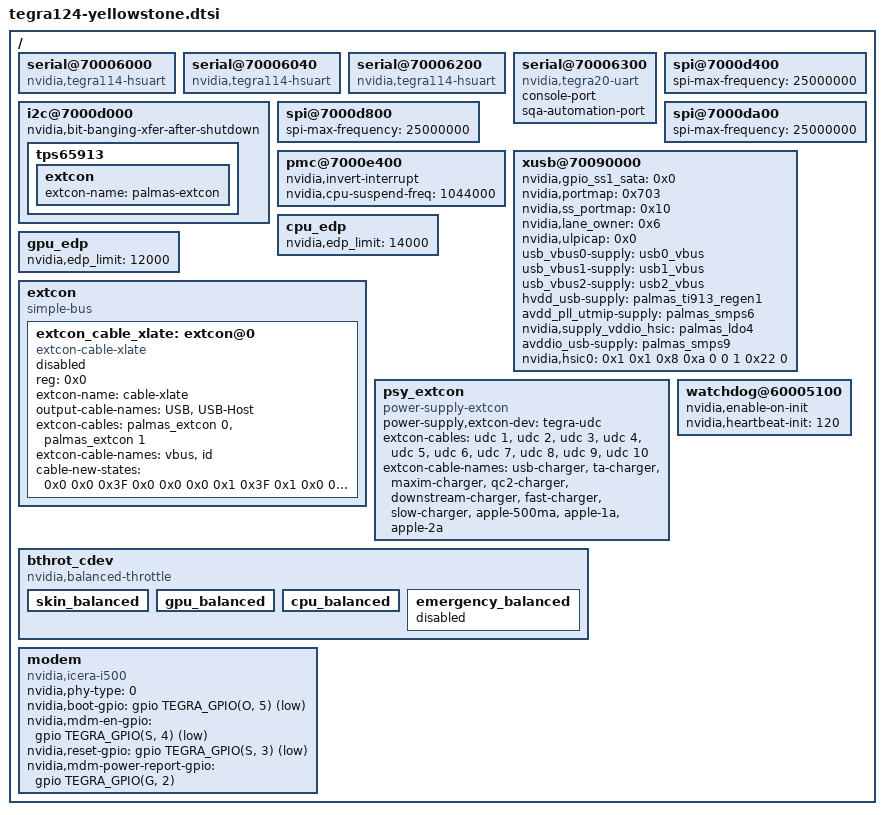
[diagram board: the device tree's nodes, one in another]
/*
 * tegra124-soc-shiled.dtsi: Shiled family SoC specific DTSI file with required node enabled.
 *
 * Copyright (c) 2013-2014, NVIDIA CORPORATION. All rights reserved.
 *
 * This program is free software; you can redistribute it and/or modify it
 * under the terms and conditions of the GNU General Public License,
 * version 2, as published by the Free Software Foundation.
 *
 * This program is distributed in the hope it will be useful, but WITHOUT
 * ANY WARRANTY; without even the implied warranty of MERCHANTABILITY or
 * FITNESS FOR A PARTICULAR PURPOSE.  See the GNU General Public License for
 * more details.
 */

#include "tegra124-soc-yellowstone.dtsi"
#include "tegra124-platforms/tegra124-yellowstone-cpufreq.dtsi"

/ {
	serial@70006000 {
		compatible = "nvidia,tegra114-hsuart";
		status = "okay";
	};

	serial@70006040 {
		compatible = "nvidia,tegra114-hsuart";
		status = "okay";
	};

	serial@70006200 {
		compatible = "nvidia,tegra114-hsuart";
		status = "okay";
	};

	serial@70006300 {
		compatible = "nvidia,tegra20-uart", "nvidia,tegra114-hsuart";
		console-port;
		sqa-automation-port;
		status = "okay";
	};

	i2c@7000d000 {
		nvidia,bit-banging-xfer-after-shutdown;

		tps65913 {
			extcon {
				extcon-name = "palmas-extcon";
			};
		};
	};

	spi@7000d400 {
		status = "okay";
		spi-max-frequency = <25000000>;
	};

	spi@7000d800 {
		status = "okay";
		spi-max-frequency = <25000000>;
	};

	spi@7000da00 {
		status = "okay";
		spi-max-frequency = <25000000>;
	};

	pmc@7000e400 {
		status = "okay";
		nvidia,invert-interrupt;
		nvidia,cpu-suspend-freq = <1044000>;
	};

	xusb@70090000 {
		/* nvidia,uses_external_pmic;
		nvidia,gpio_controls_muxed_ss_lanes; */
		nvidia,gpio_ss1_sata = <0x0>;
		nvidia,portmap = <0x703>; /* SSP0, SSP1 USB2P0, USB2P1, USBP2 */
		nvidia,ss_portmap = <0x10>;
		nvidia,lane_owner = <0x6>; /* USB3P0 USB3P1 */
		nvidia,ulpicap = <0x0>; /* No ulpi support. can we remove */
		usb_vbus0-supply = <&usb0_vbus>;
		usb_vbus1-supply = <&usb1_vbus>;
		usb_vbus2-supply = <&usb2_vbus>;
		hvdd_usb-supply = <&palmas_ti913_regen1>;
		avdd_pll_utmip-supply = <&palmas_smps6>;
		nvidia,supply_vddio_hsic = <&palmas_ldo4>;
		avddio_usb-supply = <&palmas_smps9>;
		/* hsic config values in order defined in structure */
		nvidia,hsic0 = /bits/8 <0x1 0x1 0x8 0xa 0 0 1 0x22 0>;
		status = "okay";
	};

	cpu_edp {
		status = "okay";
		nvidia,edp_limit = <14000>;
	};

	gpu_edp {
		status = "okay";
		nvidia,edp_limit = <12000>;
	};

	extcon {
		compatible = "simple-bus";
		device_type = "external-connection";
		#address-cells = <1>;
		#size-cells = <0>;
	};

	psy_extcon {
		compatible = "power-supply-extcon";
		power-supply,extcon-dev = "tegra-udc";
		extcon-cables = <&udc 1 &udc 2 &udc 3
				&udc 4 &udc 5 &udc 6
				&udc 7 &udc 8 &udc 9
				&udc 10>;
		extcon-cable-names = "usb-charger", "ta-charger", "maxim-charger",
				"qc2-charger", "downstream-charger","fast-charger",
				"slow-charger", "apple-500ma", "apple-1a",
				"apple-2a";
				status = "okay";
	};

	extcon {
		extcon_cable_xlate: extcon@0 {
			compatible = "extcon-cable-xlate";
			reg = <0x0>;
			extcon-name = "cable-xlate";
			output-cable-names = "USB", "USB-Host";
			extcon-cables = <&palmas_extcon 0 &palmas_extcon 1>;
			extcon-cable-names = "vbus", "id";
			cable-new-states = <0x0     0x0     0x3F    0x0 0x0
					0x0     0x1     0x3F    0x1   0x0
					0x2     0x1     0x3F    0x0   0x0
					0x0     0x2     0x3F    0x2   0x0
					0x0     0x3     0x3F    0x8   0x0
					0x2     0x3     0x3F    0x2   0x0
					0x3     0x1     0x3F    0x0   0x0
					0x3     0x2     0x3F    0x2   0x0
					0x0     0x5     0x3F    0x4   0x0
					0x0     0x11    0x3F    0x20  0x0
					0x11     0x1    0x3F    0x1  0x0
					0x0     0x8     0x3F    0x10  0x0>;
			#extcon-cells = <1>;
			status = "disabled";
		};
	};

	watchdog@60005100 {
		status = "okay";
		nvidia,enable-on-init;
		nvidia,heartbeat-init = <120>;
	};

	bthrot_cdev {
		compatible = "nvidia,balanced-throttle";
		skin_balanced {
			status = "okay";
		};
		gpu_balanced {
			status = "okay";
		};
		cpu_balanced {
			status = "okay";
		};
		emergency_balanced {
			status = "disabled";
		};
	};

	modem {
		compatible = "nvidia,icera-i500";
		nvidia,phy-type = <0>;

		//nvidia,regulator = "vdd_wwan_mdm";
		//vdd_wwan_mdm-supply = <&ti913_gpio2>;
		nvidia,boot-gpio = <&gpio TEGRA_GPIO(O, 5) GPIO_ACTIVE_LOW>;
		nvidia,mdm-en-gpio = <&gpio TEGRA_GPIO(S, 4) GPIO_ACTIVE_LOW>;
		nvidia,reset-gpio = <&gpio TEGRA_GPIO(S, 3) GPIO_ACTIVE_LOW>;
		nvidia,mdm-power-report-gpio = <&gpio TEGRA_GPIO(G, 2) GPIO_ACTIVE_HIGH>;

		status = "okay";
	};
};
